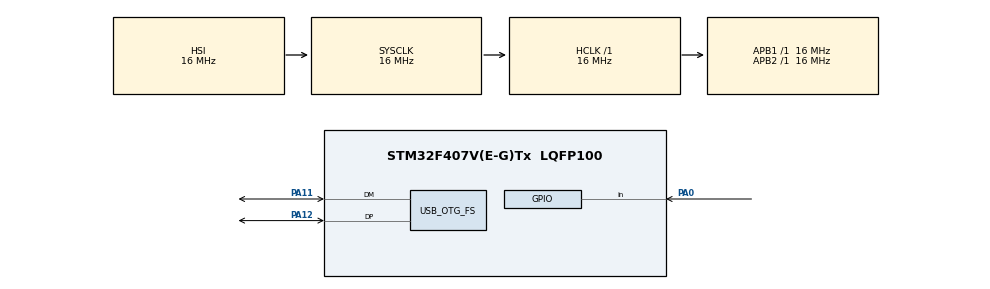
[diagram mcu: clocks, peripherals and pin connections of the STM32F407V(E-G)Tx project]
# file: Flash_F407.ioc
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Mcu.Family=STM32F4
Mcu.Name=STM32F407V(E-G)Tx
Mcu.Package=LQFP100
NVIC.OTG_FS_IRQn=true\:0\:0\:false\:false\:true\:false\:true\:true
NVIC.PriorityGroup=NVIC_PRIORITYGROUP_4
PA0-WKUP.GPIO_PuPd=GPIO_PULLDOWN
PA0-WKUP.Signal=GPIO_Input
PA11.Mode=Device_Only
PA11.Signal=USB_OTG_FS_DM
PA12.Mode=Device_Only
PA12.Signal=USB_OTG_FS_DP
PC14-OSC32_IN.Mode=LSE-External-Oscillator
PC14-OSC32_IN.Signal=RCC_OSC32_IN
PC15-OSC32_OUT.Mode=LSE-External-Oscillator
PC15-OSC32_OUT.Signal=RCC_OSC32_OUT
PH0-OSC_IN.Mode=HSE-External-Oscillator
PH0-OSC_IN.Signal=RCC_OSC_IN
PH1-OSC_OUT.Mode=HSE-External-Oscillator
PH1-OSC_OUT.Signal=RCC_OSC_OUT
ProjectManager.HeapSize=0x200
ProjectManager.StackSize=0x400
ProjectManager.TargetToolchain=STM32CubeIDE
RCC.AHBFreq_Value=16000000
RCC.APB1Freq_Value=16000000
RCC.APB2Freq_Value=16000000
RCC.CortexFreq_Value=16000000
RCC.HSE_VALUE=25000000
RCC.HSI_VALUE=16000000
RCC.PLLSource=RCC_PLLSOURCE_HSI
RCC.SYSCLKFreq_VALUE=16000000
RCC.VCOOutputFreq_Value=192000000
USB_DEVICE.CLASS_NAME_FS=CDC
USB_DEVICE.VirtualMode-CDC_FS=Cdc
USB_DEVICE.VirtualModeFS=Cdc_FS
USB_OTG_FS.VirtualMode=Device_Only
VP_CRC_VS_CRC.Mode=CRC_Activate
VP_USB_DEVICE_VS_USB_DEVICE_CDC_FS.Mode=CDC_FS
board=custom

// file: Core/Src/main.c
/* USER CODE BEGIN Header */
/**
  ******************************************************************************
  * @file           : main.c
  * @brief          : Main program body
  ******************************************************************************
  * @attention
  *
  * Copyright (c) 2025 STMicroelectronics.
  * All rights reserved.
  *
  * This software is licensed under terms that can be found in the LICENSE file
  * in the root directory of this software component.
  * If no LICENSE file comes with this software, it is provided AS-IS.
  *
  ******************************************************************************
  */
/* USER CODE END Header */
#include "main.h"
#include "usb_device.h"

/* USER CODE BEGIN Includes */
#include "CRC.h"
#include "Flash_control.h"
#include "bootloder_jumpto_app.h"
/* USER CODE END Includes */

CRC_HandleTypeDef hcrc;

void SystemClock_Config(void);
static void MX_GPIO_Init(void);
static void MX_CRC_Init(void);

/* USER CODE BEGIN 0 */
uint32_t address = 0x0800C000UL;
CommandTypeDef command_pc;
uint8_t received_data[400];
uint16_t uart_size;

FLASH_EraseInitTypeDef EraseInitStruct;
uint32_t SectorError;
/* USER CODE END 0 */

int main(void)
{

  /* MCU Configuration--------------------------------------------------------*/

  /* Reset of all peripherals, Initializes the Flash interface and the Systick. */
  HAL_Init();

  /* Configure the system clock */
  SystemClock_Config();

  /* Initialize all configured peripherals */
  MX_GPIO_Init();
  MX_USB_DEVICE_Init();
  MX_CRC_Init();

  /* Infinite loop */
	while (1) {

    /* USER CODE BEGIN 3 */
		if (uart_size) {
			if (parse_request(&command_pc, received_data, uart_size)) {
				boot_send_nack();
			} else {
				switch (command_pc.rw_request) {
				case BOOT_UPDATE_REQUSET:
					if (address == 0x0800C000UL) {
						HAL_FLASH_Unlock();
						FLASH_EraseInitTypeDef EraseInitStruct;
						uint32_t SectorError;

						EraseInitStruct.TypeErase = FLASH_TYPEERASE_SECTORS;
						EraseInitStruct.VoltageRange = FLASH_VOLTAGE_RANGE_3;
						EraseInitStruct.Sector = FLASH_SECTOR_3;
						EraseInitStruct.NbSectors = 5;

						if (HAL_FLASHEx_Erase(&EraseInitStruct, &SectorError)
								!= HAL_OK) {
							boot_send_nack();
							HAL_FLASH_Lock();
							break;
						}
						HAL_FLASH_Lock();
					}
					// ---------------------------------------------------------

					store_flash_memory(address, command_pc.data,
							command_pc.data_size);

					address += command_pc.data_size;

					boot_send_ack();
					break;
				}
			}
			uart_size = 0;
		}

		if (HAL_GPIO_ReadPin(GPIOA, GPIO_PIN_0) == 1) {
			HAL_Delay(100);
			JumpToApplication();
		}

	}
  /* USER CODE END 3 */
}

void SystemClock_Config(void)
{
  RCC_OscInitTypeDef RCC_OscInitStruct = {0};
  RCC_ClkInitTypeDef RCC_ClkInitStruct = {0};

  /** Configure the main internal regulator output voltage
  */
  __HAL_RCC_PWR_CLK_ENABLE();
  __HAL_PWR_VOLTAGESCALING_CONFIG(PWR_REGULATOR_VOLTAGE_SCALE1);

  /** Initializes the RCC Oscillators according to the specified parameters
  * in the RCC_OscInitTypeDef structure.
  */
  RCC_OscInitStruct.OscillatorType = RCC_OSCILLATORTYPE_HSI;
  RCC_OscInitStruct.HSIState = RCC_HSI_ON;
  RCC_OscInitStruct.HSICalibrationValue = RCC_HSICALIBRATION_DEFAULT;
  RCC_OscInitStruct.PLL.PLLState = RCC_PLL_ON;
  RCC_OscInitStruct.PLL.PLLSource = RCC_PLLSOURCE_HSI;
  RCC_OscInitStruct.PLL.PLLM = 16;
  RCC_OscInitStruct.PLL.PLLN = 192;
  RCC_OscInitStruct.PLL.PLLP = RCC_PLLP_DIV2;
  RCC_OscInitStruct.PLL.PLLQ = 4;
  if (HAL_RCC_OscConfig(&RCC_OscInitStruct) != HAL_OK)
  {
    Error_Handler();
  }

  /** Initializes the CPU, AHB and APB buses clocks
  */
  RCC_ClkInitStruct.ClockType = RCC_CLOCKTYPE_HCLK|RCC_CLOCKTYPE_SYSCLK
                              |RCC_CLOCKTYPE_PCLK1|RCC_CLOCKTYPE_PCLK2;
  RCC_ClkInitStruct.SYSCLKSource = RCC_SYSCLKSOURCE_HSI;
  RCC_ClkInitStruct.AHBCLKDivider = RCC_SYSCLK_DIV1;
  RCC_ClkInitStruct.APB1CLKDivider = RCC_HCLK_DIV1;
  RCC_ClkInitStruct.APB2CLKDivider = RCC_HCLK_DIV1;

  if (HAL_RCC_ClockConfig(&RCC_ClkInitStruct, FLASH_LATENCY_0) != HAL_OK)
  {
    Error_Handler();
  }
}

static void MX_CRC_Init(void)
{

  hcrc.Instance = CRC;
  if (HAL_CRC_Init(&hcrc) != HAL_OK)
  {
    Error_Handler();
  }

}

static void MX_GPIO_Init(void)
{
  GPIO_InitTypeDef GPIO_InitStruct = {0};

  /* GPIO Ports Clock Enable */
  __HAL_RCC_GPIOC_CLK_ENABLE();
  __HAL_RCC_GPIOH_CLK_ENABLE();
  __HAL_RCC_GPIOA_CLK_ENABLE();

  /*Configure GPIO pin : PA0 */
  GPIO_InitStruct.Pin = GPIO_PIN_0;
  GPIO_InitStruct.Mode = GPIO_MODE_INPUT;
  GPIO_InitStruct.Pull = GPIO_PULLDOWN;
  HAL_GPIO_Init(GPIOA, &GPIO_InitStruct);

}

void Error_Handler(void)
{
  __disable_irq();
  while (1)
  {
  }
}
